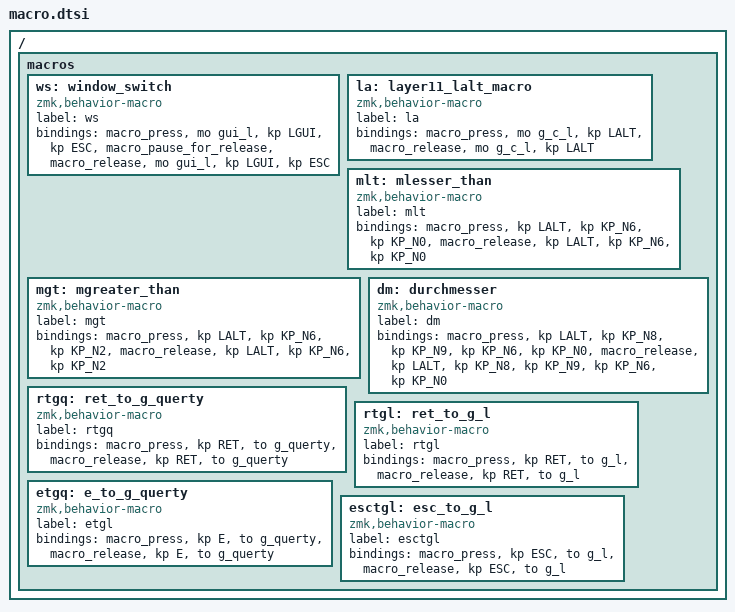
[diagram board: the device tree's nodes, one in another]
#include <behaviors.dtsi>
#include "layernames.dtsi"

 / {
    macros {
        ws: window_switch {
            compatible = "zmk,behavior-macro";
            label = "ws";
            #binding-cells = <0>;
            bindings =
                <&macro_press>,
                <&mo gui_l &kp LGUI &kp ESC>,
                <&macro_pause_for_release>,
                <&macro_release>,
                <&mo gui_l &kp LGUI &kp ESC>;
        };

        la: layer11_lalt_macro {
            compatible = "zmk,behavior-macro";
            label = "la";
            #binding-cells = <0>;
            bindings =
                <&macro_press>,
                <&mo g_c_l &kp LALT>,
                <&macro_release>,
                <&mo g_c_l &kp LALT>;
        };

        mlt: mlesser_than {
            compatible = "zmk,behavior-macro";
            label = "mlt";
            #binding-cells = <0>;
            bindings =
                <&macro_press>,
                <&kp LALT &kp KP_N6 &kp KP_N0>,
                <&macro_release>,
                <&kp LALT &kp KP_N6 &kp KP_N0>;
        };

        mgt: mgreater_than {
            compatible = "zmk,behavior-macro";
            label = "mgt";
            #binding-cells = <0>;
            bindings =
                <&macro_press>,
                <&kp LALT &kp KP_N6 &kp KP_N2>,
                <&macro_release>,
                <&kp LALT &kp KP_N6 &kp KP_N2>;
        };

        dm: durchmesser {
            compatible = "zmk,behavior-macro";
            label = "dm";
            #binding-cells = <0>;
            bindings =
                <&macro_press>,
                <&kp LALT &kp KP_N8 &kp KP_N9 &kp KP_N6 &kp KP_N0>,
                <&macro_release>,
                <&kp LALT &kp KP_N8 &kp KP_N9 &kp KP_N6 &kp KP_N0>;
        };

        // keyboard in games layer könnte man vielleicht mit sticky layers machen
        rtgq: ret_to_g_querty {
            compatible = "zmk,behavior-macro";
            label = "rtgq";
            #binding-cells = <0>;
            bindings =
                <&macro_press>,
                <&kp RET &to g_querty>,
                <&macro_release>,
                <&kp RET &to g_querty>;
        };

        rtgl: ret_to_g_l {
            compatible = "zmk,behavior-macro";
            label = "rtgl";
            #binding-cells = <0>;
            bindings =
                <&macro_press>,
                <&kp RET &to g_l>,
                <&macro_release>,
                <&kp RET &to g_l>;
        };

        etgq: e_to_g_querty {
            compatible = "zmk,behavior-macro";
            label = "etgl";
            #binding-cells = <0>;
            bindings =
                <&macro_press>,
                <&kp E &to g_querty>,
                <&macro_release>,
                <&kp E &to g_querty>;
        };

        esctgl: esc_to_g_l {
            compatible = "zmk,behavior-macro";
            label = "esctgl";
            #binding-cells = <0>;
            bindings =
                <&macro_press>,
                <&kp ESC &to g_l>,
                <&macro_release>,
                <&kp ESC &to g_l>;
        };
    };
};
